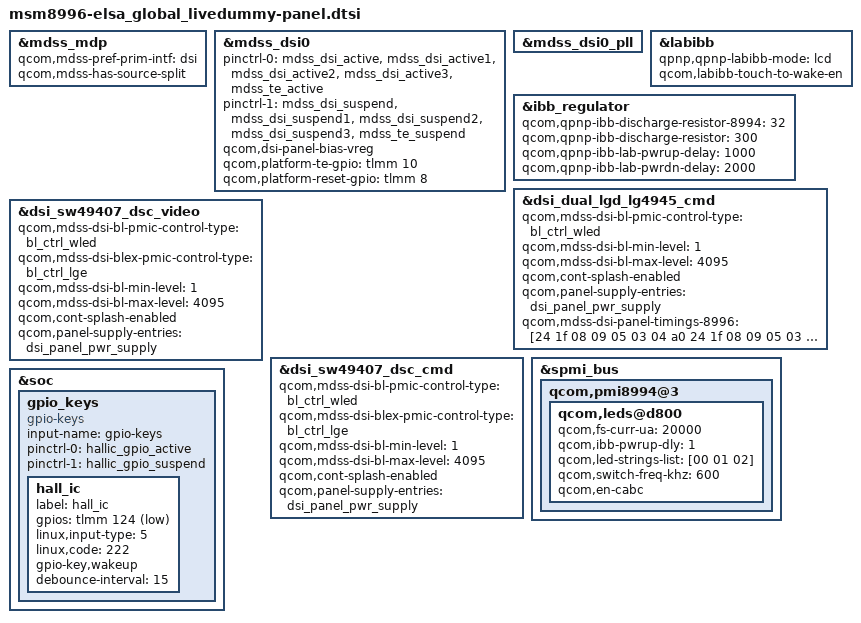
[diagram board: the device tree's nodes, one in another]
/* Copyright (c) 2015, The Linux Foundation. All rights reserved.
 *
 * This program is free software; you can redistribute it and/or modify
 * it under the terms of the GNU General Public License version 2 and
 * only version 2 as published by the Free Software Foundation.
 *
 * This program is distributed in the hope that it will be useful,
 * but WITHOUT ANY WARRANTY; without even the implied warranty of
 * MERCHANTABILITY or FITNESS FOR A PARTICULAR PURPOSE.  See the
 * GNU General Public License for more details.
 */

#include "../dsi-panel-lgd-r69007-dualmipi-qhd-cmd.dtsi"
#include "../dsi-panel-lgd-lg4945-dualmipi-qhd-cmd.dtsi"
#include "../dsi-panel-lgd-lg4946-dualmipi-qhd-cmd.dtsi"
#include "../dsi-panel-lgd-td4302-dualmipi-qhd-cmd.dtsi"
#include "../dsi-panel-sw49407-dsc-qhd-cmd.dtsi"
#include "../dsi-panel-sw49407-dsc-qhd-video.dtsi"

#include "../msm8992-panel-backlight-lm3697.dtsi"


&mdss_mdp {
	qcom,mdss-pref-prim-intf = "dsi";
	qcom,mdss-has-source-split;
};

&mdss_dsi0 {
	pinctrl-names = "mdss_default", "mdss_sleep";
	pinctrl-0 = <&mdss_dsi_active &mdss_dsi_active1 &mdss_dsi_active2 &mdss_dsi_active3 &mdss_te_active>;
	pinctrl-1 = <&mdss_dsi_suspend &mdss_dsi_suspend1 &mdss_dsi_suspend2 &mdss_dsi_suspend3 &mdss_te_suspend>;
	qcom,dsi-panel-bias-vreg;
	qcom,platform-te-gpio = <&tlmm 10 0>;
	qcom,platform-reset-gpio = <&tlmm 8 0>;

	/delete-property/vddio-supply;
};

&mdss_dsi0_pll {
		/delete-property/ memory-region;
};

&labibb {
	status = "ok";
	qpnp,qpnp-labibb-mode = "lcd";
	qcom,labibb-touch-to-wake-en;
};

&ibb_regulator {
	qcom,qpnp-ibb-discharge-resistor-8994 = <32>;
	qcom,qpnp-ibb-discharge-resistor = <300>;
	qcom,qpnp-ibb-lab-pwrup-delay = <1000>;
	qcom,qpnp-ibb-lab-pwrdn-delay = <2000>;
};

&dsi_dual_lgd_lg4945_cmd {
	qcom,mdss-dsi-bl-pmic-control-type = "bl_ctrl_wled";
	qcom,mdss-dsi-bl-min-level = <1>;
	qcom,mdss-dsi-bl-max-level = <4095>;
	qcom,cont-splash-enabled;
	qcom,panel-supply-entries = <&dsi_panel_pwr_supply>;
};

&dsi_sw49407_dsc_video {
	qcom,mdss-dsi-bl-pmic-control-type = "bl_ctrl_wled";
	qcom,mdss-dsi-blex-pmic-control-type = "bl_ctrl_lge";
	qcom,mdss-dsi-bl-min-level = <1>;
	qcom,mdss-dsi-bl-max-level = <4095>;
	qcom,cont-splash-enabled;
	qcom,panel-supply-entries = <&dsi_panel_pwr_supply>;
};

&dsi_sw49407_dsc_cmd {
	qcom,mdss-dsi-bl-pmic-control-type = "bl_ctrl_wled";
	qcom,mdss-dsi-blex-pmic-control-type = "bl_ctrl_lge";
	qcom,mdss-dsi-bl-min-level = <1>;
	qcom,mdss-dsi-bl-max-level = <4095>;
	qcom,cont-splash-enabled;
	qcom,panel-supply-entries = <&dsi_panel_pwr_supply>;
};

&spmi_bus {
	qcom,pmi8994@3 {
		qcom,leds@d800 {
			qcom,fs-curr-ua = <20000>;
			qcom,ibb-pwrup-dly = <1>;
			qcom,led-strings-list = [00 01 02];
			qcom,switch-freq-khz = <600>;
			qcom,en-cabc;
		};
	};
};

&dsi_dual_lgd_lg4945_cmd {
	qcom,mdss-dsi-panel-timings-8996 = [24 1f 08 09 05 03 04 a0
			24 1f 08 09 05 03 04 a0
			24 1f 08 09 05 03 04 a0
			24 1f 08 09 05 03 04 a0
			24 1b 08 09 05 03 04 a0];
};

&soc {
	gpio_keys {
		compatible = "gpio-keys";
		input-name = "gpio-keys";

		pinctrl-names = "tlmm_gpio_key_active","tlmm_gpio_key_suspend";
		pinctrl-0 = <&hallic_gpio_active>;
		pinctrl-1 = <&hallic_gpio_suspend>;

		hall_ic {
			label = "hall_ic";
			gpios = <&tlmm 124 0x1>;
			linux,input-type = <5>;
			linux,code = <222>;
			gpio-key,wakeup;
			debounce-interval = <15>;
		};
	};
};
